# WS63 register map
File version: 1.0
CPU: other r0p0, little endian, MPU, FPU, 3 interrupt priority bits
Registers are 32-bit, read-write, reset 0x0 unless marked. A register's access mark holds for its fields unless they carry their own. Offsets are from the block's base; [hi:lo] are bit positions; {n}, {i} and the like mark numbered series.

## LSADC — Low-speed ADC controller (12-bit SAR, 6 channels, v154)
Base 0x4400C000
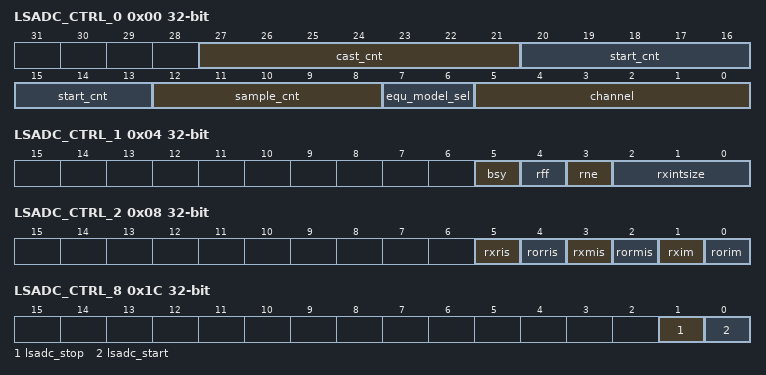
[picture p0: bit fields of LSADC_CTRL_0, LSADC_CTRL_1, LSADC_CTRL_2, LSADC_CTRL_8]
0x00 LSADC_CTRL_0 — Scan config (adc_ctrl_data): per-channel enable + sample timing. Set via hal_adc_auto_scan_mode_set.
  [27:21] cast_cnt — Cast count (7-bit)
  [20:13] start_cnt — Start count (8-bit; SDK field name satrt_cnt)
  [12:8] sample_cnt — Sample count (5-bit)
  [7:6] equ_model_sel — Averaging mode: 0=1x, 1=2x, 2=4x, 3=8x samples
  [5:0] channel — Per-channel enable bitmask (bit n enables channel n, 0-5)
0x04 LSADC_CTRL_1 — FIFO status + interrupt waterline (adc_fifo_data)
  [5] bsy ro — ADC busy
  [4] rff ro — RX FIFO full
  [3] rne ro — RX FIFO not empty
  [2:0] rxintsize — RX FIFO interrupt waterline (3-bit)
0x08 LSADC_CTRL_2 — Interrupt mask/status (adc_irg_data)
  [5] rxris ro — RX FIFO raw interrupt status
  [4] rorris ro — RX overflow raw interrupt status
  [3] rxmis ro — RX FIFO masked interrupt status
  [2] rormis ro — RX overflow masked interrupt status
  [1] rxim — RX FIFO interrupt mask
  [0] rorim — RX overflow interrupt mask
0x0C LSADC_CTRL_3 — ADC control register 3 (analog, reserved)
  [31:0] val — Raw register value
0x10 LSADC_CTRL_4 — ADC control register 4 (analog, reserved)
  [31:0] val — Raw register value
0x14 LSADC_CTRL_6 — ADC control register 6 (analog, reserved)
  [31:0] val — Raw register value
0x18 LSADC_CTRL_7 — ADC control register 7 (analog, reserved)
  [31:0] val — Raw register value
0x1C LSADC_CTRL_8 — Scan start/stop (adc_scan_start_and_stop_data)
  [1] lsadc_stop — Write 1 to stop a scan
  [0] lsadc_start — Write 1 to start a scan
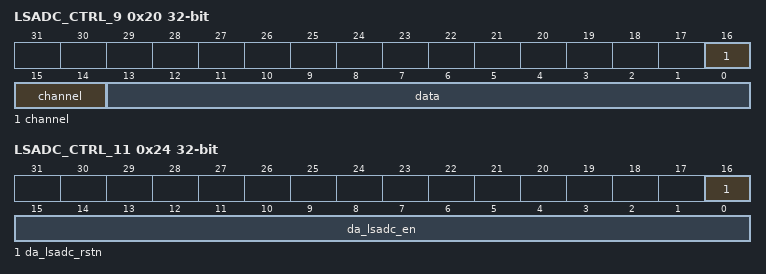
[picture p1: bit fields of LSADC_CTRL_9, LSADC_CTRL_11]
0x20 LSADC_CTRL_9 — FIFO read data (adc_fifo_read_data): 14-bit code + 3-bit channel
  [16:14] channel ro — Source channel (0-5)
  [13:0] data ro — 14-bit conversion code
0x24 LSADC_CTRL_11 — Analog enable/reset (adc_enable_data)
  [16] da_lsadc_rstn — Analog reset, active low: 1=release reset
  [15:0] da_lsadc_en — Analog block enable bits (16-bit; SDK ORs 0x7000/0xE7F/0x100/0x80 during power-up)
0x28 LSADC_CTRL_12 — ADC control register 12 (analog, reserved)
  [31:0] val — Raw register value
0xDC CFG_DATA_SEL — Data output select (base+0xDC)
  [0] data_sel — 0=raw ADC data, 1=post-processed
0xE0 CFG_OFFSET — Offset correction (base+0xE0)
  [15:0] offset — ADC offset correction
0xE4 CFG_GAIN — Gain correction (base+0xE4)
  [15:0] gain — ADC gain correction
0xE8 CFG_CIC_FILTER_EN — CIC filter enable (base+0xE8)
  [0] cic_filter_en — CIC filter enable
0xEC CFG_CIC_OSR — CIC oversampling ratio (base+0xEC)
  [7:0] cic_osr — CIC oversampling ratio

## TSENSOR — Temperature sensor controller (v151)
Base 0x4400E000
0x00 TSENSOR_CTL_ID — Temperature sensor control ID
  [15:0] tsensor_ctl_id ro — Control ID
{0x10+4i} TSENSOR_REG{i} (i=0..3) — Common register {i}
  [31:0] tsensor_reg{i} — Common configuration register {i}
0x300 TSENSOR_START — Temperature sensor start register
  [0] tsensor_start wo — Write 1 to refresh temperature reading
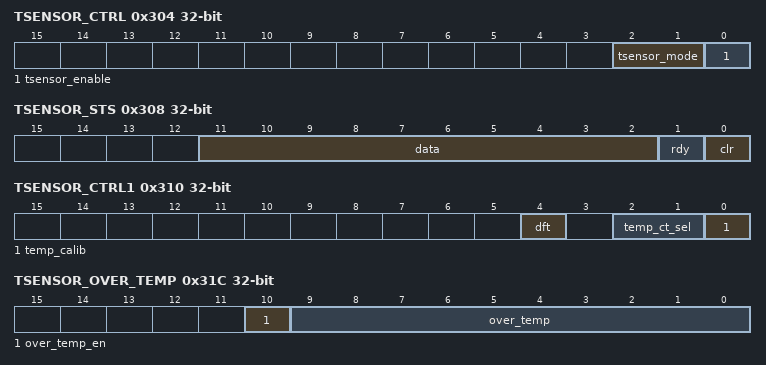
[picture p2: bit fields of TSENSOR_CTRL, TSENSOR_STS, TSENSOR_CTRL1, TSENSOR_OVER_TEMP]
0x304 TSENSOR_CTRL — Temperature sensor control register
  [2:1] tsensor_mode — Temperature sensor mode
  [0] tsensor_enable — Temperature sensor enable
0x308 TSENSOR_STS — Temperature sensor status register
  [11:2] data ro — Temperature code (10-bit, range 114-896 for -40C to 125C)
  [1] rdy ro — Data ready flag
  [0] clr — Clear status
0x310 TSENSOR_CTRL1 — Temperature sensor control 1
  [4] dft — DFT mode enable
  [2:1] temp_ct_sel — Temperature CT select
  [0] temp_calib — Temperature calibration enable
0x314 TSENSOR_TEMP_HIGH_LIMIT — High temperature limit
  [9:0] temp_high_limit — High temperature threshold (10-bit code)
0x318 TSENSOR_TEMP_LOW_LIMIT — Low temperature limit
  [9:0] temp_low_limit — Low temperature threshold (10-bit code)
0x31C TSENSOR_OVER_TEMP — Over-temperature threshold
  [10] over_temp_en — Over-temperature interrupt enable
  [9:0] over_temp — Over-temperature threshold (10-bit code)
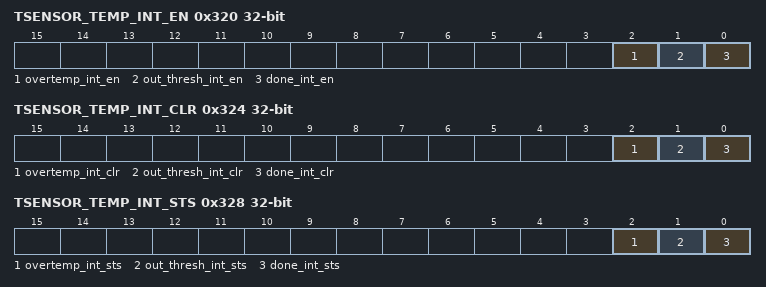
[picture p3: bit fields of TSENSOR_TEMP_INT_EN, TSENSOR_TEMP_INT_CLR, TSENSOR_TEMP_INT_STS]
0x320 TSENSOR_TEMP_INT_EN — Temperature interrupt enable
  [2] overtemp_int_en — Over-temperature interrupt enable
  [1] out_thresh_int_en — Out-of-threshold interrupt enable
  [0] done_int_en — Conversion done interrupt enable
0x324 TSENSOR_TEMP_INT_CLR — Temperature interrupt clear
  [2] overtemp_int_clr wo — Clear over-temperature interrupt
  [1] out_thresh_int_clr wo — Clear out-of-threshold interrupt
  [0] done_int_clr wo — Clear done interrupt
0x328 TSENSOR_TEMP_INT_STS — Temperature interrupt status
  [2] overtemp_int_sts ro — Over-temperature interrupt status
  [1] out_thresh_int_sts ro — Out-of-threshold interrupt status
  [0] done_int_sts ro — Conversion done interrupt status
0x330 TSENSOR_AUTO_REFRESH_PERIOD — Auto refresh period
  [15:0] auto_refresh_period — Auto refresh period in 32kHz clock cycles
0x334 TSENSOR_AUTO_REFRESH_CFG — Auto refresh configuration
  [0] auto_refresh_en — Auto refresh enable
